# C64 register map
Vendor: Commodore Business Machines; Series: Commodore 64; File version: 0.1.0
CPU: other r0p0, little endian, no MPU, no FPU, 2 interrupt priority bits
Registers are 8-bit, read-write, no defined reset value unless marked. A register's access mark holds for its fields unless they carry their own. Offsets are from the block's base; [hi:lo] are bit positions; {n}, {i} and the like mark numbered series; 'fields as' and 'values as' point back to an identical list.

## CIA2 — MOS 6526 CIA 2 at 0xDD00 (image repeats every 0x10 bytes through 0xDDFF): VIC bank select, IEC serial bus, user port, RS-232. IRQ output drives the 6510 NMI line (shared with the RESTORE key). FLAG2 is user port pin B (RS-232 RXD). SP2/CNT2 are available on the user port. Defined in full rather than derived from CIA1 so port and FLAG descriptions are correct; register layout is identical to CIA1.
Base 0x0000DD00
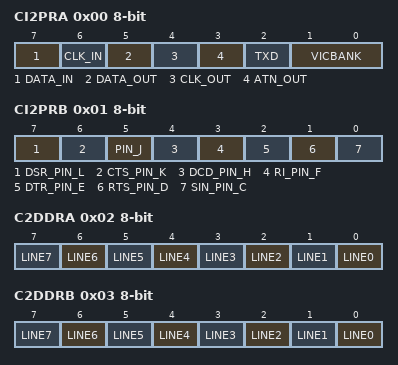
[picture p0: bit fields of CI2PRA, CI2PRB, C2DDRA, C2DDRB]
0x00 CI2PRA — Port A: VIC bank, IEC bus, RS-232 TXD. IEC outputs pass through inverting open-collector drivers: writing 1 pulls the bus line low. Inputs read the bus level directly.
  [7] DATA_IN ro — IEC DATA in
  [6] CLK_IN ro — IEC CLK in
  [5] DATA_OUT — IEC DATA out (inverted onto bus)
  [4] CLK_OUT — IEC CLK out (inverted onto bus)
  [3] ATN_OUT — IEC ATN out (inverted onto bus)
  [2] TXD — RS-232 TXD (user port pin M)
  [1:0] VICBANK — VIC-II 16 KiB video bank: Bank0 = 0x0000-0x3FFF, Bank1 = 0x4000-0x7FFF, Bank2 = 0x8000-0xBFFF, Bank3 = 0xC000-0xFFFF. The raw CIA2 bits are inverted (Bank0 = 0b11 down to Bank3 = 0b00); the enum hides that so you pick a bank by number.
    0=Bank3; 1=Bank2; 2=Bank1; 3=Bank0
0x01 CI2PRB — Port B: user port PB0-PB7 (pins C-L). KERNAL RS-232 assigns RXD to PB0 (paralleled with FLAG2) and handshake lines to PB1-PB7. General-purpose GPIO when RS-232 is unused.
  [7] DSR_PIN_L — RS-232 data set ready (DSR) / user port pin L; also Timer B toggle/pulse output
  [6] CTS_PIN_K — RS-232 clear to send (CTS) / user port pin K; also Timer A toggle/pulse output
  [5] PIN_J — User port pin J
  [4] DCD_PIN_H — RS-232 carrier detect (DCD) / user port pin H
  [3] RI_PIN_F — RS-232 ring indicator (RI) / user port pin F
  [2] DTR_PIN_E — RS-232 data terminal ready (DTR) / user port pin E
  [1] RTS_PIN_D — RS-232 request to send (RTS) / user port pin D
  [0] SIN_PIN_C — RS-232 data input (SIN) / user port pin C
0x02 C2DDRA — Port A data direction (1 = output). KERNAL sets 0x3F.
  [all] fields
    0=Input; 1=Output
  [n] LINE{n} (n=0..7) — Direction of Data Port A bit {n}
0x03 C2DDRB — Port B data direction (1 = output)
  [all] fields
    0=Input; 1=Output
  [n] LINE{n} (n=0..7) — Direction of Data Port B bit {n}
0x04 TI2ALO — Timer A bits 7:0. Read: current count. Write: latch (reload value). HI/LO reads are not latched together, so a 16-bit read can tear across a decrement: read HI, LO, re-read HI and retry on change, or stop the timer.
  [7:0] TIMER — Timer A, low 8 bits (read: counter; write: latch)
0x05 TI2AHI — Timer A bits 15:8. Read: current count. Write: latch; if the timer is stopped, writing also loads the counter.
  [7:0] TIMER — Timer A, high 8 bits (read: counter; write: latch)
0x06 TI2BLO — Timer B bits 7:0 (as TALO)
  [7:0] TIMER — Timer B, low 8 bits (read: counter; write: latch)
0x07 TI2BHI — Timer B bits 15:8 (as TAHI)
  [7:0] TIMER — Timer B, high 8 bits (read: counter; write: latch)
0x08 TO2TEN — TOD tenths of seconds, BCD. SIDE-EFFECT: reading releases the latch set by reading TO2HRS; writing (in clock mode) restarts the clock; CI2CRB.TOD_WRITE_MODE selects clock vs alarm. Same behavior as CIA1.TODTEN.
  [3:0] TENTHS — Tenths, BCD
0x09 TO2SEC — TOD seconds, BCD. SIDE-EFFECT: writes set the clock or the alarm per CI2CRB.TOD_WRITE_MODE; the read value is frozen while the TO2HRS/TO2TEN latch is held.
  [6:0] SECONDS — Seconds 00-59, BCD
0x0A TO2MIN — TOD minutes, BCD. SIDE-EFFECT: writes set the clock or the alarm per CI2CRB.TOD_WRITE_MODE; the read value is frozen while the TO2HRS/TO2TEN latch is held.
  [6:0] MINUTES — Minutes 00-59, BCD
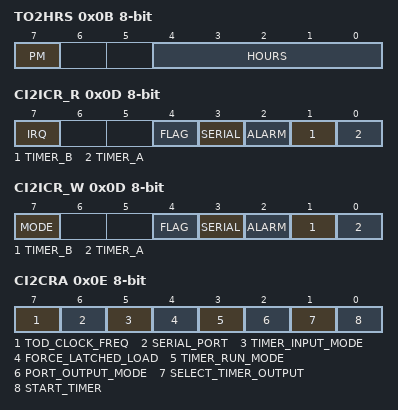
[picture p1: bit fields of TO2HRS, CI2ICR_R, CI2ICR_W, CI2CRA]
0x0B TO2HRS — TOD hours, BCD, 12-hour with PM flag. SIDE-EFFECT: reading latches all four CIA2 TOD registers until TO2TEN is read; writing (in clock mode) stops the clock until TO2TEN is written; CI2CRB.TOD_WRITE_MODE selects clock vs alarm. Same behavior as CIA1.TODHRS.
  [7] PM — 1 = PM
    0=Am; 1=Pm
  [4:0] HOURS — Hours 01-12, BCD
0x0C CI2SDR — Serial shift register on SP2, clocked by CNT2; direction set by CRA.SPMODE
  [7:0] DATA — Serial shift-register byte
0x0D CI2ICR_R ro read-clears — Interrupt data (read-only view of 0xDD0D, asserts NMI): which sources have fired. Bit 7 (IR) reads Latched if any enabled source is pending. SIDE-EFFECT: reading clears all flags and releases the line, so capture everything from one read. Set the mask via CI2ICR_W.
  [all] fields
    0=Inactive; 1=Latched
  [7] IRQ — Any enabled source latched (this read also clears all flags)
  [4] FLAG — FLAG2 negative edge (user port pin B / RS-232 RXD start bit)
  [3] SERIAL — Serial register full/empty
  [2] ALARM — TOD alarm match
  [1] TIMER_B — Timer B underflow
  [0] TIMER_A — Timer A underflow
0x0D CI2ICR_W wo (alternate view of CI2ICR_R) — Interrupt mask (write-only alternate view of 0xDD0D). Enable or disable individual NMI sources without disturbing the others: `set()` the sources you want to change, then let `mode()` pick the direction — `mode().enabled()` enables every source you `set()`, `mode().disabled()` disables them. Sources left `clear()` (the default) are untouched either way. Read status via CI2ICR_R. SIDE-EFFECT: this write changes which interrupts are enabled.
  [7] MODE — Direction for this write: `enabled()` enables every source bit you `set()`; `disabled()` disables them. Sources left `clear()` are untouched either way. SIDE-EFFECT: the (un)mask takes effect immediately.
    0=Disabled; 1=Enabled
  [4] FLAG — FLAG interrupt mask select. `set()` marks the FLAG source for change; the direction (enable vs disable) comes from `mode()`. `clear()` (default) leaves it untouched. Setting this alone does nothing without `mode()`.
    0=Clear (Leave this source's mask unchanged); 1=Set (Select this source for the update chosen by MODE)
  [3] SERIAL — Serial interrupt mask select. `set()` marks the serial source for change; the direction (enable vs disable) comes from `mode()`. `clear()` (default) leaves it untouched. Setting this alone does nothing without `mode()`.
    values as FLAG
  [2] ALARM — TOD alarm interrupt mask select. `set()` marks the alarm for change; the direction (enable vs disable) comes from `mode()`. `clear()` (default) leaves it untouched. Setting this alone does nothing without `mode()`.
    values as FLAG
  [1] TIMER_B — Timer B interrupt mask select. `set()` marks Timer B for change; the direction (enable vs disable) comes from `mode()`. `clear()` (default) leaves Timer B untouched. Setting this alone does nothing without `mode()`.
    values as FLAG
  [0] TIMER_A — Timer A interrupt mask select. `set()` marks Timer A for change; the direction (enable vs disable) comes from `mode()`. `clear()` (default) leaves Timer A untouched. Setting this alone does nothing without `mode()`.
    values as FLAG
0x0E CI2CRA — Control register A (same layout as CIA1.CRA; the timer-output bits act on this CIA's PB6). Bit 4 (FORCE_LATCHED_LOAD) is a write-only strobe that always reads back 0, so it appears on the writer only
  [7] TOD_CLOCK_FREQ — TOD clock input frequency
    0=Hz60; 1=Hz50
  [6] SERIAL_PORT — Serial-port shift-register direction
    0=Input; 1=Output
  [5] TIMER_INPUT_MODE — What timer A counts
    0=CpuCycles; 1=UserPortCnt
  [4] FORCE_LATCHED_LOAD wo — Force-load timer A from its latch. A strobe: writing Execute performs the load, writing Idle does nothing. Write-only, hence no reader: the bit always reads back Idle no matter what was last written, so a read carries no information about the hardware. SIDE-EFFECT: writing Execute copies the latch into the counter immediately.
    0=Idle; 1=Execute
  [3] TIMER_RUN_MODE — Timer A reload behavior after underflow
    0=Continuous; 1=OneShot
  [2] PORT_OUTPUT_MODE — PB6 output waveform on timer A underflow
    0=PulseBit6; 1=ToggleBit6
  [1] SELECT_TIMER_OUTPUT — Route timer A underflow onto PB6 (Enabled) instead of using it as general I/O (Disabled)
    0=Disabled; 1=Enabled
  [0] START_TIMER — Start/stop timer A. SIDE-EFFECT: writing Enabled begins the count immediately.
    0=Disabled; 1=Enabled
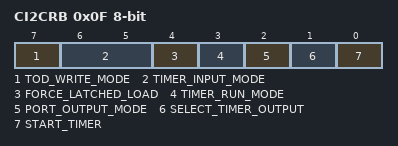
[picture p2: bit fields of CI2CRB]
0x0F CI2CRB — Control register B (same layout as CIA1.CRB; the timer-output bits act on this CIA's PB7). Bit 4 (FORCE_LATCHED_LOAD) is a write-only strobe that always reads back 0, so it appears on the writer only
  [7] TOD_WRITE_MODE — Selects what TOD register writes set: clock or alarm
    0=Clock; 1=Alarm
  [6:5] TIMER_INPUT_MODE — What timer B counts
    0=CpuCycles; 1=UserPortCnt; 2=TaUnderflow; 3=TaUnderflowWhileCntHigh
  [4] FORCE_LATCHED_LOAD wo — Force-load timer B from its latch. A strobe: writing Execute performs the load, writing Idle does nothing. Write-only, hence no reader: the bit always reads back Idle no matter what was last written, so a read carries no information about the hardware. SIDE-EFFECT: writing Execute copies the latch into the counter immediately.
    0=Idle; 1=Execute
  [3] TIMER_RUN_MODE — Timer B reload behavior after underflow
    0=Continuous; 1=OneShot
  [2] PORT_OUTPUT_MODE — PB7 output waveform on timer B underflow
    0=PulseBit7; 1=ToggleBit7
  [1] SELECT_TIMER_OUTPUT — Route timer B underflow onto PB7 (Enabled) instead of using it as general I/O (Disabled)
    0=Disabled; 1=Enabled
  [0] START_TIMER — Start/stop timer B. SIDE-EFFECT: writing Enabled begins the count immediately.
    0=Disabled; 1=Enabled
